# STM32H533 register map
File version: 1.3
CPU: CM33 r0p0, little endian, MPU, FPU, 4 interrupt priority bits
Registers are 32-bit, read-write, reset 0x0 unless marked. A register's access mark holds for its fields unless they carry their own. Offsets are from the block's base; [hi:lo] are bit positions.

## ADCC — ADC common registers block
Base 0x42028300
Same registers: SEC_ADCC 0x52028300
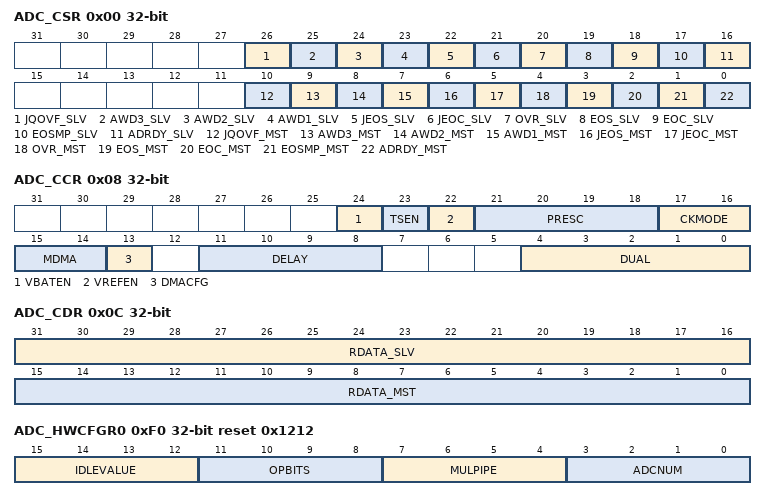
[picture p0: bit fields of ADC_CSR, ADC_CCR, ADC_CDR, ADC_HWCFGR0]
0x00 ADC_CSR ro — ADC common status register
  [26] JQOVF_SLV — Injected Context Queue Overflow flag of the slave ADC
  [25] AWD3_SLV — Analog watchdog 3 flag of the slave ADC
  [24] AWD2_SLV — Analog watchdog 2 flag of the slave ADC
  [23] AWD1_SLV — Analog watchdog 1 flag of the slave ADC
  [22] JEOS_SLV — End of injected sequence flag of the slave ADC
  [21] JEOC_SLV — End of injected conversion flag of the slave ADC
  [20] OVR_SLV — Overrun flag of the slave ADC
  [19] EOS_SLV — End of regular sequence flag of the slave ADC.
  [18] EOC_SLV — End of regular conversion of the slave ADC
  [17] EOSMP_SLV — End of Sampling phase flag of the slave ADC
  [16] ADRDY_SLV — Slave ADC ready
  [10] JQOVF_MST — Injected Context Queue Overflow flag of the master ADC
  [9] AWD3_MST — Analog watchdog 3 flag of the master ADC
  [8] AWD2_MST — Analog watchdog 2 flag of the master ADC
  [7] AWD1_MST — Analog watchdog 1 flag of the master ADC
  [6] JEOS_MST — End of injected sequence flag of the master ADC
  [5] JEOC_MST — End of injected conversion flag of the master ADC
  [4] OVR_MST — Overrun flag of the master ADC
  [3] EOS_MST — End of regular sequence flag of the master ADC
  [2] EOC_MST — End of regular conversion of the master ADC
  [1] EOSMP_MST — End of Sampling phase flag of the master ADC
  [0] ADRDY_MST — Master ADC ready
0x08 ADC_CCR — ADC common control register
  [24] VBATEN — VBAT enable
    0=Vless thansub>BATless than/sub> channel disabled; 1=Vless thansub>BATless than/sub> channel enabled
  [23] TSEN — Vless thansub>SENSEless than/sub> enable
    0=Temperature sensor channel disabled; 1=Temperature sensor channel enabled
  [22] VREFEN — Vless thansub>REFINTless than/sub> enable
    0=Vless thansub>REFINTless than/sub> channel disabled; 1=Vless thansub>REFINTless than/sub> channel enabled
  [21:18] PRESC — ADC prescaler
    0=input ADC clock not divided; 1=input ADC clock divided by 2; 2=input ADC clock divided by 4; 3=input ADC clock divided by 6; 4=input ADC clock divided by 8; 5=input ADC clock divided by 10; 6=input ADC clock divided by 12; 7=input ADC clock divided by 16; 8=input ADC clock divided by 32; 9=input ADC clock divided by 64; 10=input ADC clock divided by 128; 11=input ADC clock divided by 256
  [17:16] CKMODE — ADC clock mode
    0=adc_ker_ck (x = 1/2) (Asynchronous clock mode), generated at product level (refer to Section6: Reset and clock control (RCC)); 1=adc_hclk/1 (Synchronous clock mode); 2=adc_hclk/2 (Synchronous clock mode); 3=adc_hclk/4 (Synchronous clock mode)
  [15:14] MDMA — Direct memory access mode for dual ADC mode
    0=MDMA mode disabled; 2=MDMA mode enabled for 12 and 10-bit resolution; 3=MDMA mode enabled for 8 and 6-bit resolution
  [13] DMACFG — DMA configuration (for dual ADC mode)
    0=DMA One Shot mode selected; 1=DMA Circular mode selected
  [11:8] DELAY — Delay between 2 sampling phases
  [4:0] DUAL — Dual ADC mode selection
    0=Independent mode; 1=Combined regular simultaneous + injected simultaneous mode; 2=Combined regular simultaneous + alternate trigger mode; 3=Combined interleaved mode + injected simultaneous mode; 5=Injected simultaneous mode only; 6=Regular simultaneous mode only; 7=Interleaved mode only; 9=Alternate trigger mode only
0x0C ADC_CDR ro — ADC common regular data register for dual mode
  [31:16] RDATA_SLV — Regular data of the slave ADC
  [15:0] RDATA_MST — Regular data of the master ADC.
0xF0 ADC_HWCFGR0 ro reset 0x1212 — ADC hardware configuration register
  [15:12] IDLEVALUE — Idle value for non-selected channels
    0=Dummy channel selection is 0x13; 1=Dummy channel selection is 0x1F
  [11:8] OPBITS — Number of option bits
    0=No option register implemented; 1=1 option bit implemented in the ADC option register (ADC_OR) at address offset 0xC8
  [7:4] MULPIPE — Number of pipeline stages
    1=One-stage pipeline
  [3:0] ADCNUM — Number of ADCs implemented
    1=One ADC instance implemented; 2=Two ADC instances implemented; 3=Three ADCs instances implemented
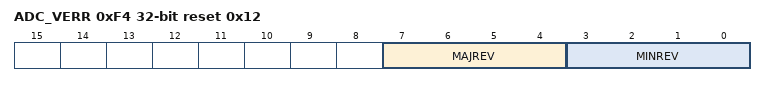
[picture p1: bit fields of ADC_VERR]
0xF4 ADC_VERR ro reset 0x12 — ADC version register
  [7:4] MAJREV — Major revision
    1=Major revision = 1
  [3:0] MINREV — Minor revision
    1=Minor revision = X
0xF8 ADC_IPDR ro reset 0x110006 — ADC identification register
  [31:0] ID — Peripheral identifier
0xFC ADC_SIDR ro reset 0xA3C5DD01 — ADC size identification register
  [31:0] SID — Size Identification
    1=1Kbytes address offset; 2=2Kbytes address offset; 4=4Kbytes address offset; 8=8 Kbytes address offset
